# ISP_CSI2A register map
Vendor: Texas Instruments
Peripheral module from a debugger description file (folder omap34xx).
Registers are 32-bit, read-write, reset 0x0 unless marked. A register's access mark holds for its fields unless they carry their own. Offsets are as the file gives them; lines under a group give offsets from that group; [hi:lo] are bit positions; {n}, {i} and the like mark numbered series; 'fields as' and 'values as' point back to an identical list; <NAME> marks a mode.

## ISP_CSI2A
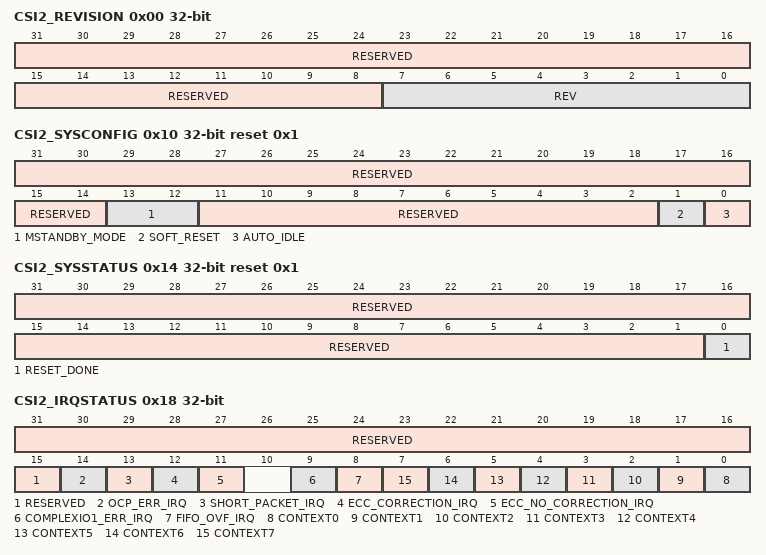
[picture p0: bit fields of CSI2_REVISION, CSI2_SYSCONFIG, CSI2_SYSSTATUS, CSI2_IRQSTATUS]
0x00 CSI2_REVISION ro (reset mask 0xFFFFFF00) — MODULE REVISION This register contains the IP revision code in binary coded digital. For example, we have: 0x01 = revision 0.1 and 0x21 = revision 2.1
  [31:8] RESERVED — Write 0s for future compatibility.Reads returns 0.
  [7:0] REV — IP revision [7:4] Major revision[3:0] Minor revision
0x10 CSI2_SYSCONFIG reset 0x1 — SYSTEM CONFIGURATION REGISTER This register is the OCP-socket system configuration register.
  [31:14] RESERVED — Write 0s for future compatibility.Reads returns 0.
  [13:12] MSTANDBY_MODE — Sets the behavior of the master port power management signals.
    0=Force-standby. Hardware signal is only asserted when the module is disabled.; 1=No-standby. Hardware signal is never asserted.; 2=Smart-standby: Hardware signal is asserted based on the activity of the module. The module tries to go to standby during the vertical blanking period.
  [11:2] RESERVED — Write 0s for future compatibility.Reads returns 0.
  [1] SOFT_RESET — Software reset. Set the bit to 1 to trigger a module reset. The bit is automatically reset by the HW. During reads return 0.
    0=Normal mode; 1=The module is reset
  [0] AUTO_IDLE — Internal OCP gating strategy
    0=OCP clock is free-running; 1=Automatic OCP clock gating strategy is applied based on the OCP interface activity
0x14 CSI2_SYSSTATUS ro reset 0x1 — SYSTEM STATUS REGISTER This register provides status information about the module, excluding the interrupt status register.
  [31:1] RESERVED — Reads returns 0.
  [0] RESET_DONE — Internal reset monitoring
    0=Internal module reset is on going; 1=Reset completed
0x18 CSI2_IRQSTATUS access per field — INTERRUPT STATUS REGISTER - All contexts This register associates one bit for each context to determine which context has generated the interrupt. The context must be enabled for events to be generated on that context. If the context is disabled, the interrupt is not generated.
  [31:15] RESERVED rw — Write 0s for future compatibility.Reads returns 0.
  [14] OCP_ERR_IRQ rw — OCP Error Interrupt
    0=READS: Event is false. WRITES: Status bit unchanged.; 1=READS: Event is true (pending). WRITES: Status bit is reset.
  [13] SHORT_PACKET_IRQ rw — Short packet reception status (other than sync events: Line Start, Line End, Frame Start, and Frame End: data type between 0x8 and x0F only must be considered).
    values as OCP_ERR_IRQ
  [12] ECC_CORRECTION_IRQ rw — ECC has been used to do the correction of the only 1-bit error status (short packet only).
    values as OCP_ERR_IRQ
  [11] ECC_NO_CORRECTION_IRQ rw — ECC error status (short and long packets). No correction of the header because of more than 1-bit error.
    values as OCP_ERR_IRQ
  [9] COMPLEXIO1_ERR_IRQ ro — Error signaling from Complex I/O #1: status of the PHY errors received from the complex I/O #1 (events are defined inCSI2_COMPLEXIO1_IRQSTATUS for the 1st complex I/O).
    0=READS: Event is false; 1=READS: Event is true (pending)
  [8] FIFO_OVF_IRQ rw — FIFO overflow error status.
    values as OCP_ERR_IRQ
  [n] CONTEXT{n} ro (n=0..7)
    0=READS: Event is false; 1=READS: Event is true (pending)
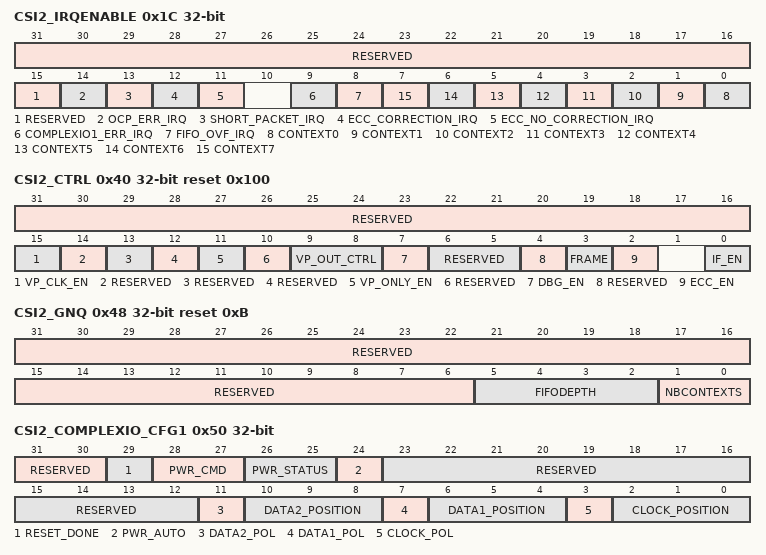
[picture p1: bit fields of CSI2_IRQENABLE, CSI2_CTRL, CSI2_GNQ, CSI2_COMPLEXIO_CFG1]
0x1C CSI2_IRQENABLE — INTERRUPT ENABLE REGISTER - All contexts This register associates one bit for each context to enable/disable each context individually.
  [31:15] RESERVED — Write 0s for future compatibility.Reads returns 0.
  [14] OCP_ERR_IRQ — OCP Error Interrupt
    0=Event is masked; 1=Event generates an interrupt when it occurs
  [13] SHORT_PACKET_IRQ — Short packet reception (other than sync events: Line Start, Line End, Frame Start, and Frame End: data type between 0x8 and x0F only must be considered).
    values as OCP_ERR_IRQ
  [12] ECC_CORRECTION_IRQ — ECC has been used to correct the only 1-bit error (short packet only).
    values as OCP_ERR_IRQ
  [11] ECC_NO_CORRECTION_IRQ — ECC error (short and long packets). No correction of the header because of more than 1-bit error.
    values as OCP_ERR_IRQ
  [9] COMPLEXIO1_ERR_IRQ — Error signaling from Complex I/O #1: the interrupt is triggered when any error is received from the complex I/O #1 (events are defined inCSI2_COMPLEXIO1_IRQSTATUS for the 1st complex I/O).
    values as OCP_ERR_IRQ
  [8] FIFO_OVF_IRQ — FIFO overflow enable
    values as OCP_ERR_IRQ
  [n] CONTEXT{n} (n=0..7)
    values as OCP_ERR_IRQ
0x40 CSI2_CTRL reset 0x100 — GLOBAL CONTROL REGISTER This register controls the CSI2 RECEIVER module. This register must not be modified dynamically (except IF_EN bit field).
  [31:16] RESERVED — Write 0s for future compatibility.Reads returns 0.
  [15] VP_CLK_EN — VP clock enable.
    0=The VP clock is disabled; 1=The VP clock is enabled
  [14] RESERVED — Write 0s for future compatibility.Reads returns 0.
  [13] RESERVED — Write 0s for future compatibility.Reads returns 0.
  [12] RESERVED — Write 0s for future compatibility.Reads returns 0.
  [11] VP_ONLY_EN — VP only enable.
    0=The VP is enabled and the OCP master port is enabled; 1=The VP is enabled and the OCP master port is disabled
  [10] RESERVED — Write 0s for future compatibility.Reads returns 0.
  [9:8] VP_OUT_CTRL — Video port output clock control. Sets the video port output clock as a function of the interface clock (OCPCLK).
    0=No division: video port clock = OCPCLK; 1=Division by 2: video port clock = OCPCLK/2; 2=Division by 3: video port clock = OCPCLK/3; 3=Division by 4: video port clock = OCPCLK/4
  [7] DBG_EN — Enables the debug mode.
    0=Disable; 1=Enable
  [6:5] RESERVED — Write 0s for future compatibility.Reads returns 0.
  [4] RESERVED — Write 0s for future compatibility.Reads returns 0.
  [3] FRAME — Set the modality in which IF_EN works.
    0=If IF_EN = 0 the interface is disabled immediately; 1=If IF_EN = 1 the interface is disabled after all FEC sync code have been received for the active contexts
  [2] ECC_EN — Enables the Error Correction Code check for the received header (short and long packets for all virtual channel ids).
    0=Disabled; 1=Enabled
  [0] IF_EN — Enables the physical interface to the module.
    0=The interface is disabled. If FRAME = 0, it is disabled immediately. If FRAME = 1, it is disabled when each context has received the FEC sync code.; 1=The interface is enabled immediately, the data acquisition starts on the next FSC sync code. Writing 1 to this register when the current value is 0 has the effect to clear the output FIFO. The pixel data of the following frame are written in the PING buffer, that is, the.PING_PONG bits are reset to 0 as well.
0x44 CSI2_DBG_H wo — DEBUG REGISTER (Header) This register provides a way to debug the CSI2 RECEIVER module with no image sensor connected to the module. The debug mode is enabled by.DBG_EN. Only full 32-bit values must be written. The register is used to write short packets and header of long packets.
  [31:0] DBG — 32-bit input value.
0x48 CSI2_GNQ ro reset 0xB — GENERIC PARAMETER REGISTER This register provide a way to read the generic parameters used in the design.
  [31:6] RESERVED — Write 0s for future compatibility.Reads returns 0.
  [5:2] FIFODEPTH — Output FIFO size in multiple of 68 bits.
    2=8x 68 bits; 3=16x 68 bits; 4=32x 68 bits; 5=64x 68 bits; 6=128 x 68 bits; 7=256 x 68 bits
  [1:0] NBCONTEXTS — Number of contexts supported by the module.
    0=1 Context; 1=2 Contexts; 2=4 Contexts; 3=8 Contexts
0x50 CSI2_COMPLEXIO_CFG1 access per field — COMPLEXIO CONFIGURATION REGISTER for the complex I/O #1 This register contains the lane configuration for the order and position of the lanes (clock and data) and the polarity order for the control of the PHY differential signals in addition to the control bit for the power FSM.
  [31:30] RESERVED rw — Write 0s for future compatibility.Reads returns 0.
  [29] RESET_DONE ro — Internal reset monitoring of the power domain using the PPI byte clock from the complex io
    0=Internal module reset is on going; 1=Reset completed
  [28:27] PWR_CMD rw — Command for power control of the complex io
    0=Command to change to OFF state; 1=Command to change to ON state; 2=Command to change to Ultra Low Power state
  [26:25] PWR_STATUS ro — Status of the power control of the complex io
    0=Complex I/O in OFF state; 1=Complex I/O in ON state; 2=Complex I/O in ultra-low power state
  [24] PWR_AUTO rw — Automatic switch between ULP and ON states based on ULPM signals from complex I/O
    0=Disable; 1=Enable
  [23:12] RESERVED rw — Write 0s for future compatibility. Reads returns 0.
  [11] DATA2_POL rw — +/- differential pin order of DATA lane 2.
    0=+/- pin order (csi2_dx=+ and csi2_dy=-); 1=-/+ pin order (csi2_dx=- and csi2_dy=+)
  [10:8] DATA2_POSITION rw — Position and order of the DATA lane 2.
    0=Not used/connected; 1=Data lane 2 is at the position 1; 2=Data lane 2 is at the position 2; 3=Data lane 2 is at the position 3
  [7] DATA1_POL rw — +/- differential pin order of DATA lane 1.
    values as DATA2_POL
  [6:4] DATA1_POSITION rw — Position and order of the DATA lane 1. The data lane 1 is always present.
    0=Not used/connected; 1=Data lane 1 is at the position 1; 2=Data lane 1 is at the position 2; 3=Data lane 1 is at the position 3
  [3] CLOCK_POL rw — +/- differential pin order of CLOCK lane.
    values as DATA2_POL
  [2:0] CLOCK_POSITION rw — Position and order of the CLOCK lane. The clock lane is always present.
    0=Not used/connected; 1=Clock lane is at the position 1; 2=Clock lane is at the position 2; 3=Clock lane is at the position 3
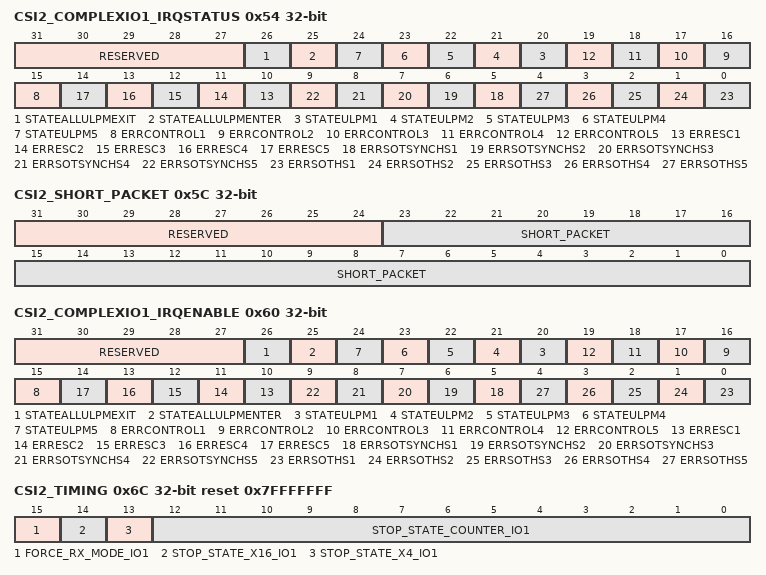
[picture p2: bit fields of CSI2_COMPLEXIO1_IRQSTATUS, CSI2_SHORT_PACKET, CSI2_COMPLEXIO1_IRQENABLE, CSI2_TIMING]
0x54 CSI2_COMPLEXIO1_IRQSTATUS access not given — INTERRUPT STATUS REGISTER - All errors from complex I/O #1
  [31:27] RESERVED ro — Write 0s for future compatibility.Reads returns 0.
  [26] STATEALLULPMEXIT — At least one of the active lanes has exit the ULPM (access RW W1toClr)
    values as CSI2_IRQSTATUS.OCP_ERR_IRQ
  [25] STATEALLULPMENTER — All active lanes are entering in ULPM. (access RW W1toClr)
    values as CSI2_IRQSTATUS.OCP_ERR_IRQ
  [n+19] STATEULPM{n} (n=1..5) — Lane #{n} in Ultra Low Power Mode (access RW W1toClr)
    values as CSI2_IRQSTATUS.OCP_ERR_IRQ
  [n+14] ERRCONTROL{n} (n=1..5) — Control error for lane #{n} (access RW W1toClr)
    values as CSI2_IRQSTATUS.OCP_ERR_IRQ
  [n+9] ERRESC{n} (n=1..5) — Escape entry error for lane #{n} (access RW W1toClr)
    values as CSI2_IRQSTATUS.OCP_ERR_IRQ
  [n+4] ERRSOTSYNCHS{n} (n=1..5) — Start of transmission sync error for lane #{n} (access RW W1toClr)
    values as CSI2_IRQSTATUS.OCP_ERR_IRQ
  [n-1] ERRSOTHS{n} (n=1..5) — Start of transmission error for lane #{n} (access RW W1toClr)
    values as CSI2_IRQSTATUS.OCP_ERR_IRQ
0x5C CSI2_SHORT_PACKET ro — SHORT PACKET INFORMATION - This register sets the 24-bit DATA_ID + Short Packet Data Field when the data type is between 0x8 and x0F
  [31:24] RESERVED — Reads returns 0.
  [23:0] SHORT_PACKET — Short Packet information: DATA ID + DATA FIELD
0x60 CSI2_COMPLEXIO1_IRQENABLE — INTERRUPT ENABLE REGISTER - All errors from complex I/O #1
  [31:27] RESERVED — Write 0s for future compatibility.Reads returns 0.
  [26] STATEALLULPMEXIT — At least one of the active lanes has exit the ULPM
    values as CSI2_IRQENABLE.OCP_ERR_IRQ
  [25] STATEALLULPMENTER — All active lanes are entering in ULPM.
    values as CSI2_IRQENABLE.OCP_ERR_IRQ
  [n+19] STATEULPM{n} (n=1..5) — Lane #{n} in Ultra Low Power Mode
    values as CSI2_IRQENABLE.OCP_ERR_IRQ
  [n+14] ERRCONTROL{n} (n=1..5) — Control error for lane #{n}
    values as CSI2_IRQENABLE.OCP_ERR_IRQ
  [n+9] ERRESC{n} (n=1..5) — Escape entry error for lane #{n}
    values as CSI2_IRQENABLE.OCP_ERR_IRQ
  [n+4] ERRSOTSYNCHS{n} (n=1..5) — Start of transmission sync error for lane #{n}
    values as CSI2_IRQENABLE.OCP_ERR_IRQ
  [n-1] ERRSOTHS{n} (n=1..5) — Start of transmission error for lane #{n}
    values as CSI2_IRQENABLE.OCP_ERR_IRQ
0x68 CSI2_DBG_P wo — DEBUG REGISTER (Payload) This register provides a way to debug the CSI2 RECEIVER module with no image sensor connected to the module. The debug mode is enabled by.DBG_EN. The register is used to write payload of long packets.
  [31:0] DBG — 32-bit input value.
0x6C CSI2_TIMING reset 0x7FFFFFFF — TIMING REGISTER This register controls the CSI2 RECEIVER module. This register must not be modified while.IF_EN is set to 1. It is used to indicate the number of L3 cycles for the Stop State monitoring.
  [15] FORCE_RX_MODE_IO1 — Control of ForceRxMode signal
    0=De-assertion of ForceRxMode. The HW reset the bit at the end of the Force RX Mode assertion. The SW can reset the bit to stop the assertion of the ForceRXMode signal prior to the completion of the period.; 1=Assertion of ForceRxMode
  [14] STOP_STATE_X16_IO1 — Multiplication factor for the number of L3 cycles defined in STOP_STATE_COUNTER_IO1 bit-field
    0=The number of L3 cycles defined in STOP_STATE _COUNTER_IO1 is multiplied by 1x; 1=The number of L3 cycles defined in STOP_STATE _COUNTER_IO1 is multiplied by 16x
  [13] STOP_STATE_X4_IO1 — Multiplication factor for the number of L3 cycles defined in STOP_STATE_COUNTER_IO1 bit-field
    0=The number of L3 cycles defined in STOP_STATE _COUNTER_IO1 is multiplied by 1x; 1=The number of L3 cycles defined in STOP_STATE _COUNTER_IO1 is multiplied by 4x
  [12:0] STOP_STATE_COUNTER_IO1 — Stop State counter for monitoring. It indicates the number of L3 cycles to monitor for Stop State before de-asserting ForceRxMode (Complex I/O #1).The value is from 0 to 8191.
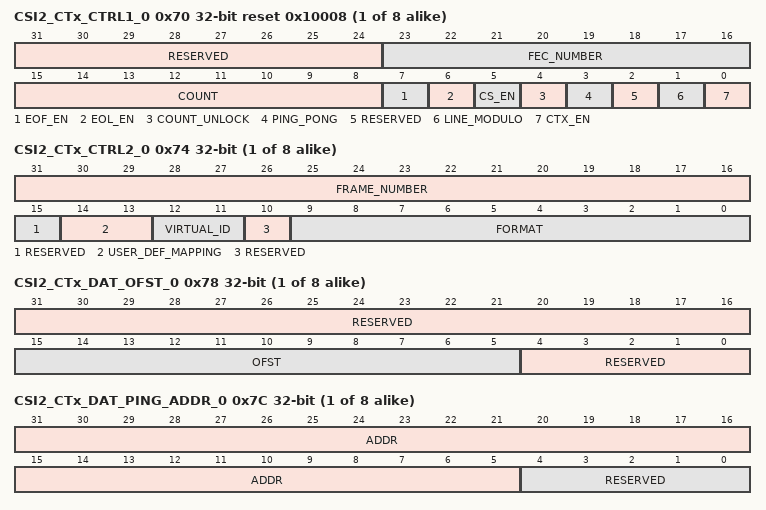
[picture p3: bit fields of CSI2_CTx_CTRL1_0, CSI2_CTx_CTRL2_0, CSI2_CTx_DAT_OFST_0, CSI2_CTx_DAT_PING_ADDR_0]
{0x70+0x20*i} CSI2_CTx_CTRL1_{i} access per field reset 0x10008 (i=0..7) — CONTROL REGISTER - Context This register controls the Context. This register is shadowed: modifications are taken into account after the next FSC sync code.
  [31:24] RESERVED rw — Write 0s for future compatibility.Reads returns 0.
  [23:16] FEC_NUMBER rw — Number of FEC to receive between using swap ofCSI2_CTx_DAT_PING_ADDR and CSI2_CTx_DAT_PONG_ADDR for the calculation of the address in memory. (must be used only in interlace mode, otherwise set to 1)
  [15:8] COUNT rw — Sets the number of frame to acquire. Once the frame acquisition starts, the COUNT value is decremented after every frame. When COUNT reaches 0, the FRAME_NUMBER_IRQ interrupt is triggered and CTX_EN is set to 0. Writes to this bit field are controlled by the COUNT_UNLOCK bit. During the same OCP write access , the bit-field COUNT_UNLOCK must be written in addition to COUNT bit-field to change the COUNT value. COUNT can be overwritten dynamically with a new count value.' 0: Infinite number of frames (no count).1: 1 frame to acquire...255: 255 frames to acquire.
  [7] EOF_EN rw — Indicates if the end of frame signal must be asserted at the end of the frame.
    0=The end of frame signal is not asserted at the end of each frame; 1=The end of frame signal is asserted at the end of each frame
  [6] EOL_EN rw — Indicates if the end of line signal must be asserted at the end of the line.
    0=The end of line signal is not asserted at the end of each line; 1=The end of line signal is asserted at the end of each line
  [5] CS_EN rw — Enables the checksum check for the received payload (long packet only).
    0=Disabled; 1=Enabled
  [4] COUNT_UNLOCK wo — Unlock writes to the COUNT bit field.
    0=COUNT bit field is locked. Writes have no effect; 1=COUNT bit field is unlocked. Writes are possible.
  [3] PING_PONG ro — Indicates whether the PING or PONG destination address (CSI2_CTx_DAT_PING_ADDR or CSI2_CTx_DAT_PONG_ADDR) was used to write the last frame. This bit field toggles after every FEC sync code received for the current context.
    0=PING buffer; 1=PONG buffer
  [2] RESERVED rw — Write 0s for future compatibility.Reads returns 0.
  [1] LINE_MODULO rw — Line modulo configuration
    0=.LINE_NUMBER is used once per frame for the generation of the LINE_NUMBER_IRQ; 1=.LINE_NUMBER is used as a modulo number for the generation of the LINE_NUMBER_IRQ (multiple times the interrupt can be generated for each frame)
  [0] CTX_EN rw — Enables the Context
    0=Disabled; 1=Enabled
{0x74+0x20*i} CSI2_CTx_CTRL2_{i} access per field (i=0..7) — CONTROL REGISTER - Context This register controls the Context. This register is shadowed: modifications are taken into account after the next FSC sync code (except for VIRTUAL_ID and FORMAT fields). The change of VIRTUAL_ID and FORMAT has to occur only when the context is disabled (.CTX_EN).
  [31:16] FRAME_NUMBER ro — Frame number received
  [15] RESERVED rw — Write 0s for future compatibility.Reads returns 0.
  [14:13] USER_DEF_MAPPING rw — Selects the pixel format of USER_DEFINED in FORMAT
    0=RAW6; 1=RAW7; 2=RAW8 (not valid if FORMAT is USER_DEFINED_8_BIT_DATA_TYPE_x_EXP8 with x from 1 to 8)
  [12:11] VIRTUAL_ID rw — Virtual channel ID
    {v}=Virtual Channel ID {v} (v=0..3)
  [10] RESERVED rw — Write 0s for future compatibility.Reads returns 0.
  [9:0] FORMAT rw — Data format selection.
    0=OTHERS (except NULL and BLANKING packets); 18=Embedded 8-bit non-image data (that is, JPEG); 24=YUV420 8bit; 25=YUV420 10bit; 26=YUV420 8bit legacy; 28=YUV420 8bit + CSPS; 29=YUV420 10bit + CSPS; 30=YUV422 8bit; 31=YUV422 10bit; 34=RGB565; 36=RGB888; 40=RAW6; 41=RAW7; 42=RAW8; 43=RAW10; 44=RAW12; 45=RAW14; 51=RGB666 + EXP32_24; {v}=USER_DEFINED_8_BIT_DATA_TYPE_{v-63} (v=64..71); 104=RAW6 + EXP8; 105=RAW7 + EXP8; {v}=USER_DEFINED_8_BIT_DATA_TYPE_{v-127} + EXP8 (v=128..135); 158=YUV422 8bit + VP; 160=RGB444 + EXP16; 161=RGB555 + EXP16; 171=RAW10 + EXP16; 172=RAW12 + EXP16; 173=RAW14 + EXP16; 227=RGB666 + EXP32; 228=RGB888 + EXP32; 0x12A=RAW8 + VP; 0x12C=RAW12 + VP; 0x12D=RAW14 + VP; 0x12F=RAW10 + VP
{0x78+0x20*i} CSI2_CTx_DAT_OFST_{i} (i=0..7) — DATA MEM ADDRESS OFFSET REGISTER - Context This register sets the offset, which is applied on the destination address after each line is written to memory. This register applies for both and . For example, it enables to perform 2D data transfers of the pixel data into a frame buffer. In such case, the pixel data and frame buffer data must have the same data format. Note that the 5 LSBs are ignored: the offset must be a multiple of 32 bytes. This register is shadowed: modifications are taken into account after the next FSC sync code. Only full 32-bit values must be written.
  [31:16] RESERVED — Write 0s for future compatibility.Reads returns 0.
  [15:5] OFST — Line offset programmed in bytes (signed value 2's complement). If OFST = 0, the data is written contiguously in memory. Otherwise, OFST sets the destination offset between the first pixel of the previous line and the first pixel of the current line.
  [4:0] RESERVED — Write 0s for future compatibility.Reads returns 0.
{0x7C+0x20*i} CSI2_CTx_DAT_PING_ADDR_{i} (i=0..7) — DATA MEM PING ADDRESS REGISTER - Context This register sets the 32-bit memory address where the pixel data are stored. The destination is double buffered: this register sets the PING address. Double buffering is enabled when the addresses and are different. Note that the 5 LSBs are ignored: the address should be aligned on a 32-byte boundary. This register is shadowed: modifications are taken into account after the next FSC sync code. Only full 32-bit values must be written.
  [31:5] ADDR — 27 most significant bits of the 32-bit address.
  [4:0] RESERVED — 5 least significant bits of the 32-bit address. Write 0s for future compatibility.Reads returns 0.
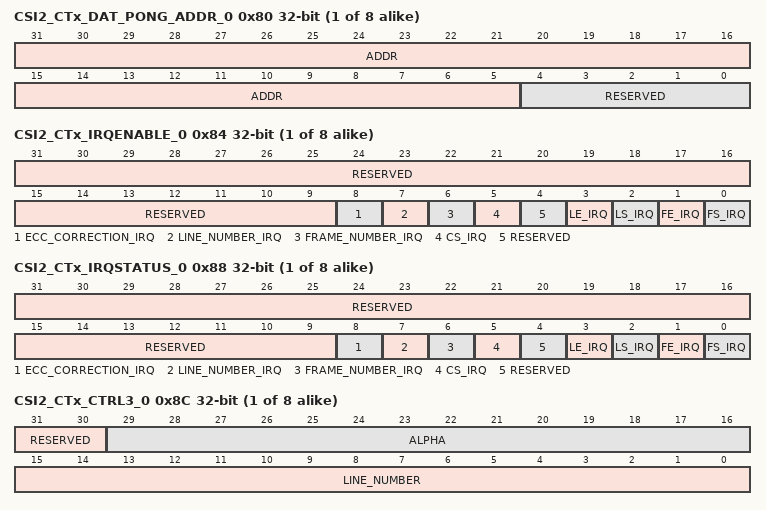
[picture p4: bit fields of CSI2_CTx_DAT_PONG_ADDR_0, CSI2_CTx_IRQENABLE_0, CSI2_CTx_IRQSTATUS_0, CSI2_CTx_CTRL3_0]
{0x80+0x20*i} CSI2_CTx_DAT_PONG_ADDR_{i} (i=0..7) — DATA MEM PONG ADDRESS REGISTER - Context This register sets the 32-bit memory address where the pixel data are stored. The destination is double buffered: this register sets the PONG address. Double buffering is enabled when the addresses and are different. Note that the 5 LSBs are ignored: the address should be aligned on a 32-byte boundary. This register is shadowed: modifications are taken into account after the next FSC sync code. Only full 32-bit values must be written.
  fields as CSI2_CTx_DAT_PING_ADDR_0
{0x84+0x20*i} CSI2_CTx_IRQENABLE_{i} (i=0..7) — INTERRUPT ENABLE REGISTER - Context This register regroups all the events related to Context.
  [31:9] RESERVED — Write 0s for future compatibility.Reads returns 0.
  [8] ECC_CORRECTION_IRQ — Context - ECC has been used to correct the only 1-bit error (long packet only).
    values as CSI2_IRQENABLE.OCP_ERR_IRQ
  [7] LINE_NUMBER_IRQ — Context - Line number is reached.
    values as CSI2_IRQENABLE.OCP_ERR_IRQ
  [6] FRAME_NUMBER_IRQ — Context - Frame counter reached.
    values as CSI2_IRQENABLE.OCP_ERR_IRQ
  [5] CS_IRQ — Context - Check-Sum of the payload mismatch detection
    values as CSI2_IRQENABLE.OCP_ERR_IRQ
  [4] RESERVED — Write 0s for future compatibility.Reads returns 0.
  [3] LE_IRQ — Context - Line end sync code detection.
    values as CSI2_IRQENABLE.OCP_ERR_IRQ
  [2] LS_IRQ — Context - Line start sync code detection.
    values as CSI2_IRQENABLE.OCP_ERR_IRQ
  [1] FE_IRQ — Context - Frame end sync code detection.
    values as CSI2_IRQENABLE.OCP_ERR_IRQ
  [0] FS_IRQ — Context - Frame start sync code detection.
    values as CSI2_IRQENABLE.OCP_ERR_IRQ
{0x88+0x20*i} CSI2_CTx_IRQSTATUS_{i} access not given (i=0..7) — INTERRUPT STATUS REGISTER - Context This register regroups all the events related to Context.
  [31:9] RESERVED ro — Write 0s for future compatibility.Reads returns 0.
  [8] ECC_CORRECTION_IRQ — Context - ECC has been used to do the correction of the only 1-bit error status (long packet only). (access RW W1toClr)
    values as CSI2_IRQSTATUS.OCP_ERR_IRQ
  [7] LINE_NUMBER_IRQ — Context - Line number reached status. (access RW W1toClr)
    values as CSI2_IRQSTATUS.OCP_ERR_IRQ
  [6] FRAME_NUMBER_IRQ — Context - Frame counter reached status (access RW W1toClr)
    values as CSI2_IRQSTATUS.OCP_ERR_IRQ
  [5] CS_IRQ — Context - Check-Sum mismatch status. (access RW W1toClr)
    0=READS: Event is false. WRITES: Status bit unchanged; 1=READS: Event is true (pending). WRITES: Status bit is reset.
  [4] RESERVED ro — Write 0s for future compatibility.Reads returns 0.
  [3] LE_IRQ — Context - Line end sync code detection status. (access RW W1toClr)
    values as CSI2_IRQSTATUS.OCP_ERR_IRQ
  [2] LS_IRQ — Context - Line start sync code detection status. (access RW W1toClr)
    values as CSI2_IRQSTATUS.OCP_ERR_IRQ
  [1] FE_IRQ — Context - Frame end sync code detection status. (access RW W1toClr)
    values as CSI2_IRQSTATUS.OCP_ERR_IRQ
  [0] FS_IRQ — Context - Frame start sync code detection status. (access RW W1toClr)
    values as CSI2_IRQSTATUS.OCP_ERR_IRQ
{0x8C+0x20*i} CSI2_CTx_CTRL3_{i} (i=0..7) — CONTROL REGISTER - Context This register controls the Context. This register is shadowed: modifications are taken into account after the next FSC sync code.
  [31:30] RESERVED — Write 0s for future compatibility.Reads returns 0.
  [29:16] ALPHA — Alpha value for RGB888, RGB666 and RBG444.
  [15:0] LINE_NUMBER — Line number for the interrupt generation
